# STM32L471QEI3 register map
File version: 1.0
Registers are 32-bit, access not given, reset 0x0 unless marked. A register's access mark holds for its fields unless they carry their own. Offsets are from the block's base; [hi:lo] are bit positions; {n}, {i} and the like mark numbered series.

## DAC1
Base 0x40007400
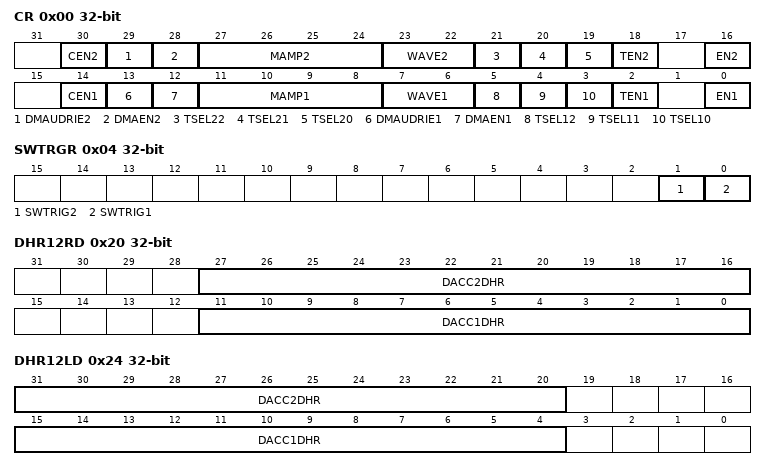
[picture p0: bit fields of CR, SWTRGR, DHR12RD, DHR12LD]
0x00 CR
  [30] CEN2, [29] DMAUDRIE2, [28] DMAEN2, [27:24] MAMP2, [23:22] WAVE2, [21] TSEL22, [20] TSEL21, [19] TSEL20, [18] TEN2, [16] EN2, [14] CEN1, [13] DMAUDRIE1, [12] DMAEN1, [11:8] MAMP1, [7:6] WAVE1, [5] TSEL12, [4] TSEL11, [3] TSEL10, [2] TEN1, [0] EN1
0x04 SWTRGR
  [1] SWTRIG2, [0] SWTRIG1
0x08 DHR12R1
  [11:0] DACC1DHR
0x0C DHR12L1
  [15:4] DACC1DHR
0x10 DHR8R1
  [7:0] DACC1DHR
0x14 DHR12R2
  [11:0] DACC2DHR
0x18 DHR12L2
  [15:4] DACC2DHR
0x1C DHR8R2
  [7:0] DACC2DHR
0x20 DHR12RD
  [27:16] DACC2DHR, [11:0] DACC1DHR
0x24 DHR12LD
  [31:20] DACC2DHR, [15:4] DACC1DHR
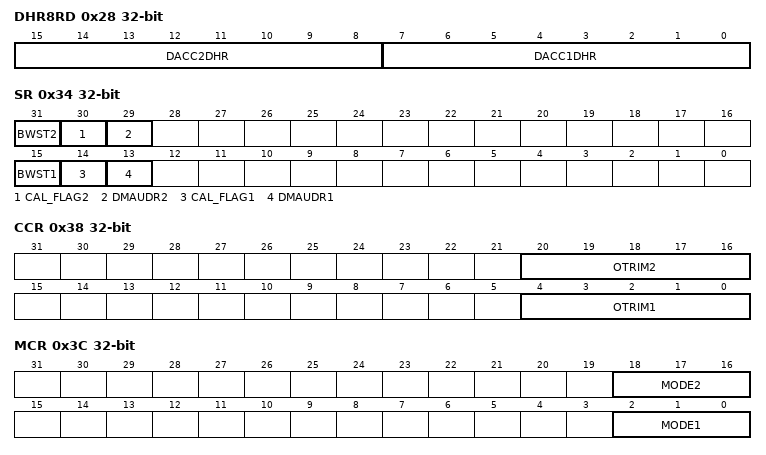
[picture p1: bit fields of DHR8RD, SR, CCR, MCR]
0x28 DHR8RD
  [15:8] DACC2DHR, [7:0] DACC1DHR
0x2C DOR1
  [11:0] DACC1DOR
0x30 DOR2
  [11:0] DACC2DOR
0x34 SR
  [31] BWST2, [30] CAL_FLAG2, [29] DMAUDR2, [15] BWST1, [14] CAL_FLAG1, [13] DMAUDR1
0x38 CCR
  [20:16] OTRIM2, [4:0] OTRIM1
0x3C MCR
  [18:16] MODE2, [2:0] MODE1
0x40 SHSR1
  [9:0] TSAMPLE1
0x44 SHSR2
  [9:0] TSAMPLE2
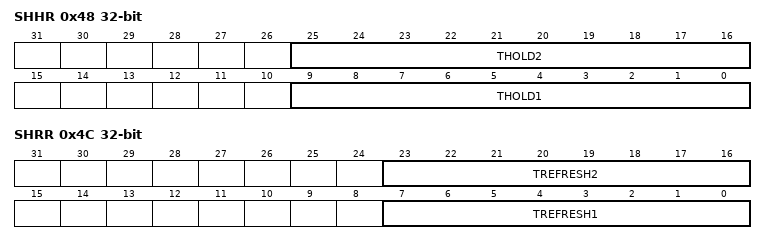
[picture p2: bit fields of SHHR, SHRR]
0x48 SHHR
  [25:16] THOLD2, [9:0] THOLD1
0x4C SHRR
  [23:16] TREFRESH2, [7:0] TREFRESH1

## OPAMP
Base 0x40007800
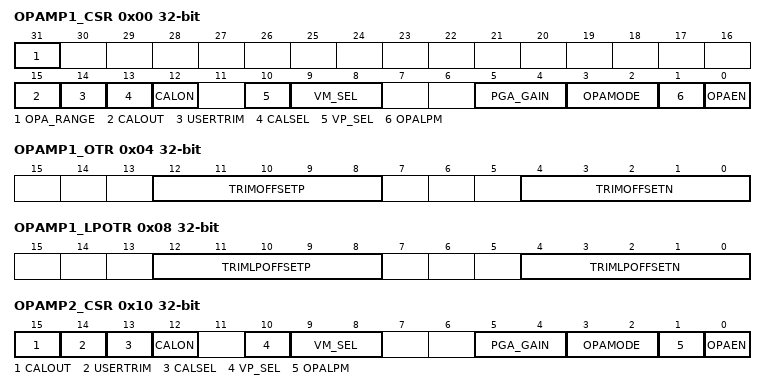
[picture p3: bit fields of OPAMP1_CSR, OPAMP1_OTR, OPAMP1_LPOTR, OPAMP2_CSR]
0x00 OPAMP1_CSR
  [31] OPA_RANGE, [15] CALOUT, [14] USERTRIM, [13] CALSEL, [12] CALON, [10] VP_SEL, [9:8] VM_SEL, [5:4] PGA_GAIN, [3:2] OPAMODE, [1] OPALPM, [0] OPAEN
0x04 OPAMP1_OTR
  [12:8] TRIMOFFSETP, [4:0] TRIMOFFSETN
0x08 OPAMP1_LPOTR
  [12:8] TRIMLPOFFSETP, [4:0] TRIMLPOFFSETN
0x10 OPAMP2_CSR
  [15] CALOUT, [14] USERTRIM, [13] CALSEL, [12] CALON, [10] VP_SEL, [9:8] VM_SEL, [5:4] PGA_GAIN, [3:2] OPAMODE, [1] OPALPM, [0] OPAEN
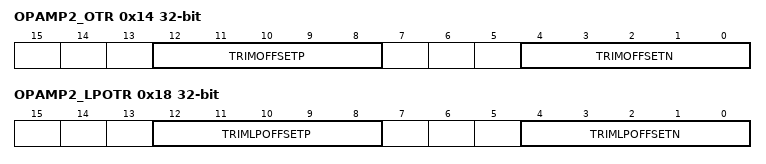
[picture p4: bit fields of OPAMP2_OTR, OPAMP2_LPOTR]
0x14 OPAMP2_OTR
  [12:8] TRIMOFFSETP, [4:0] TRIMOFFSETN
0x18 OPAMP2_LPOTR
  [12:8] TRIMLPOFFSETP, [4:0] TRIMLPOFFSETN

## LPTIM1
Base 0x40007C00
Same registers: LPTIM2 0x40009400
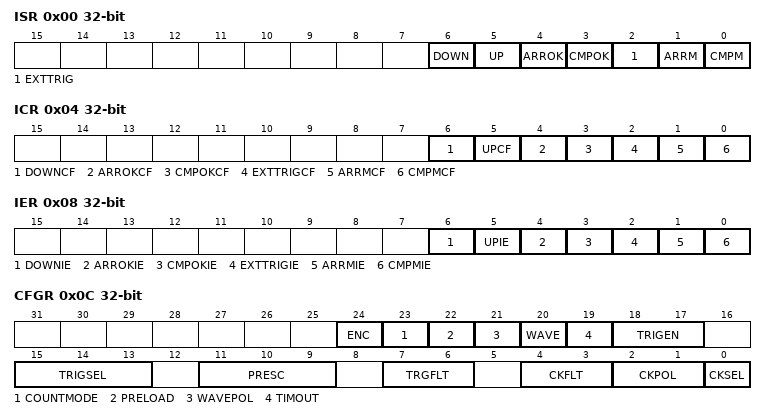
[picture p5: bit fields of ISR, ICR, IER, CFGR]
0x00 ISR
  [6] DOWN, [5] UP, [4] ARROK, [3] CMPOK, [2] EXTTRIG, [1] ARRM, [0] CMPM
0x04 ICR
  [6] DOWNCF, [5] UPCF, [4] ARROKCF, [3] CMPOKCF, [2] EXTTRIGCF, [1] ARRMCF, [0] CMPMCF
0x08 IER
  [6] DOWNIE, [5] UPIE, [4] ARROKIE, [3] CMPOKIE, [2] EXTTRIGIE, [1] ARRMIE, [0] CMPMIE
0x0C CFGR
  [24] ENC, [23] COUNTMODE, [22] PRELOAD, [21] WAVEPOL, [20] WAVE, [19] TIMOUT, [18:17] TRIGEN, [15:13] TRIGSEL, [11:9] PRESC, [7:6] TRGFLT, [4:3] CKFLT, [2:1] CKPOL, [0] CKSEL
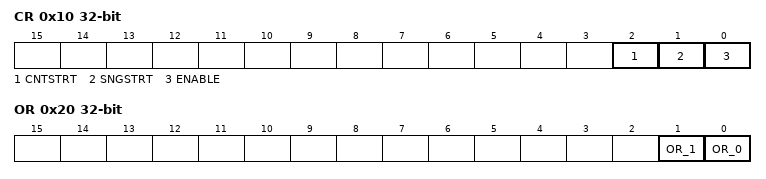
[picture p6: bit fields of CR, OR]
0x10 CR
  [2] CNTSTRT, [1] SNGSTRT, [0] ENABLE
0x14 CMP
  [15:0] CMP
0x18 ARR
  [15:0] ARR
0x1C CNT
  [15:0] CNT
0x20 OR
  [1] OR_1, [0] OR_0

## LPUART1
Base 0x40008000
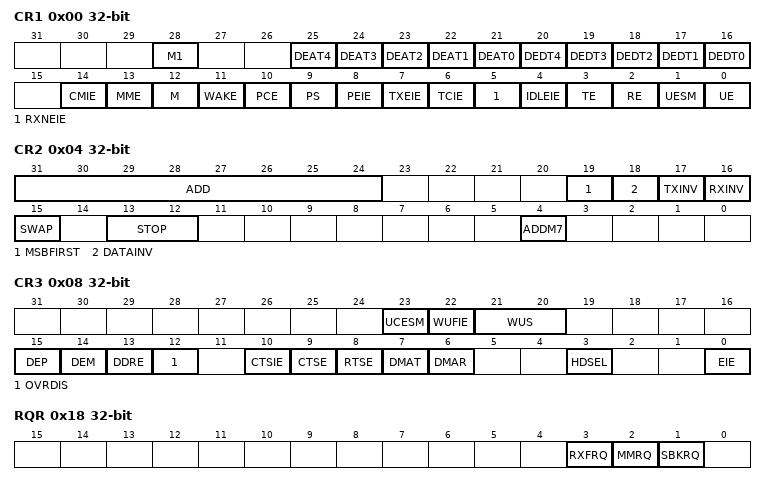
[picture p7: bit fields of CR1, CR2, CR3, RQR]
0x00 CR1
  [28] M1, [n+21] DEAT{n} (n=0..4), [n+16] DEDT{n} (n=0..4), [14] CMIE, [13] MME, [12] M, [11] WAKE, [10] PCE, [9] PS, [8] PEIE, [7] TXEIE, [6] TCIE, [5] RXNEIE, [4] IDLEIE, [3] TE, [2] RE, [1] UESM, [0] UE
0x04 CR2
  [31:24] ADD, [19] MSBFIRST, [18] DATAINV, [17] TXINV, [16] RXINV, [15] SWAP, [13:12] STOP, [4] ADDM7
0x08 CR3
  [23] UCESM, [22] WUFIE, [21:20] WUS, [15] DEP, [14] DEM, [13] DDRE, [12] OVRDIS, [10] CTSIE, [9] CTSE, [8] RTSE, [7] DMAT, [6] DMAR, [3] HDSEL, [0] EIE
0x0C BRR
  [19:0] BRR
0x18 RQR
  [3] RXFRQ, [2] MMRQ, [1] SBKRQ
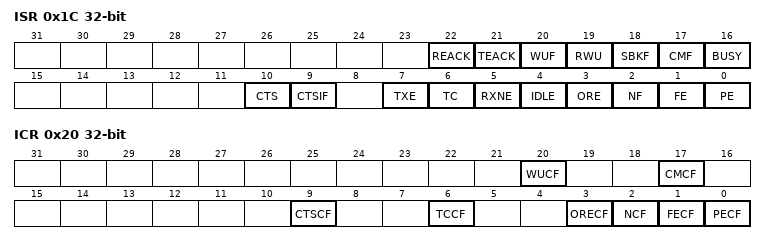
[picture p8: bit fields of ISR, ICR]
0x1C ISR
  [22] REACK, [21] TEACK, [20] WUF, [19] RWU, [18] SBKF, [17] CMF, [16] BUSY, [10] CTS, [9] CTSIF, [7] TXE, [6] TC, [5] RXNE, [4] IDLE, [3] ORE, [2] NF, [1] FE, [0] PE
0x20 ICR
  [20] WUCF, [17] CMCF, [9] CTSCF, [6] TCCF, [3] ORECF, [2] NCF, [1] FECF, [0] PECF
0x24 RDR
  [8:0] RDR
0x28 TDR
  [8:0] TDR

## SWPMI1
Base 0x40008800
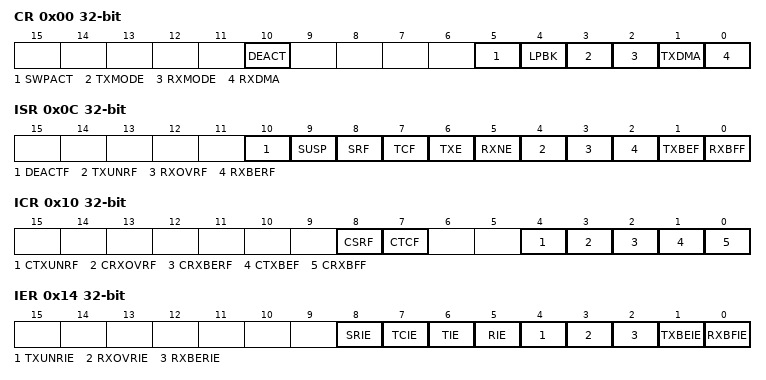
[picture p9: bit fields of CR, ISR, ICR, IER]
0x00 CR
  [10] DEACT, [5] SWPACT, [4] LPBK, [3] TXMODE, [2] RXMODE, [1] TXDMA, [0] RXDMA
0x04 BRR
  [5:0] BRR
0x0C ISR
  [10] DEACTF, [9] SUSP, [8] SRF, [7] TCF, [6] TXE, [5] RXNE, [4] TXUNRF, [3] RXOVRF, [2] RXBERF, [1] TXBEF, [0] RXBFF
0x10 ICR
  [8] CSRF, [7] CTCF, [4] CTXUNRF, [3] CRXOVRF, [2] CRXBERF, [1] CTXBEF, [0] CRXBFF
0x14 IER
  [8] SRIE, [7] TCIE, [6] TIE, [5] RIE, [4] TXUNRIE, [3] RXOVRIE, [2] RXBERIE, [1] TXBEIE, [0] RXBFIE
0x18 RFL
  [4:0] RFL
0x1C TDR
  [31:0] TD
0x20 RDR
  [31:0] RD
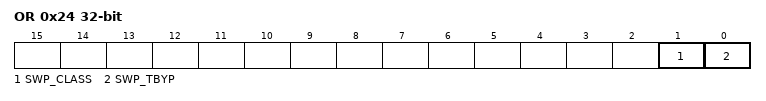
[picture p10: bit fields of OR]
0x24 OR
  [1] SWP_CLASS, [0] SWP_TBYP
